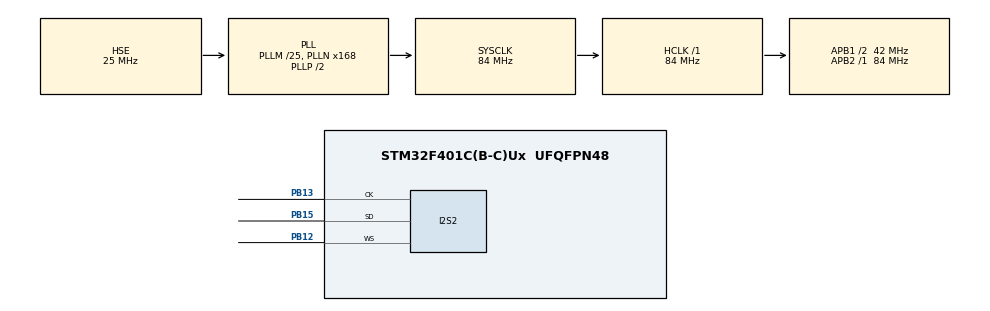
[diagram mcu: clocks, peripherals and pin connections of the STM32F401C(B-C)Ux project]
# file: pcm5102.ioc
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Dma.Request0=SPI2_TX
Dma.SPI2_TX.0.Direction=DMA_MEMORY_TO_PERIPH
Dma.SPI2_TX.0.FIFOMode=DMA_FIFOMODE_DISABLE
Dma.SPI2_TX.0.Instance=DMA1_Stream4
Dma.SPI2_TX.0.MemDataAlignment=DMA_MDATAALIGN_HALFWORD
Dma.SPI2_TX.0.MemInc=DMA_MINC_ENABLE
Dma.SPI2_TX.0.Mode=DMA_CIRCULAR
Dma.SPI2_TX.0.PeriphDataAlignment=DMA_PDATAALIGN_HALFWORD
Dma.SPI2_TX.0.PeriphInc=DMA_PINC_DISABLE
Dma.SPI2_TX.0.Priority=DMA_PRIORITY_LOW
I2S2.AudioFreq=I2S_AUDIOFREQ_48K
I2S2.ErrorAudioFreq=-0.79 %
I2S2.FullDuplexMode=I2S_FULLDUPLEXMODE_DISABLE
I2S2.Instance=SPI$Index
I2S2.RealAudioFreq=47.619 KHz
I2S2.Standard=I2S_STANDARD_PHILIPS
I2S2.VirtualMode=I2S_MODE_MASTER
Mcu.Family=STM32F4
Mcu.Name=STM32F401C(B-C)Ux
Mcu.Package=UFQFPN48
NVIC.DMA1_Stream4_IRQn=true\:0\:0\:false\:false\:true\:false\:true
NVIC.PriorityGroup=NVIC_PRIORITYGROUP_4
NVIC.TIM1_UP_TIM10_IRQn=true\:0\:0\:false\:false\:true\:true\:true
PA13.Mode=Serial_Wire
PA13.Signal=SYS_JTMS-SWDIO
PA14.Mode=Serial_Wire
PA14.Signal=SYS_JTCK-SWCLK
PB12.Mode=Half_Duplex_Master
PB12.Signal=I2S2_WS
PB13.Mode=Half_Duplex_Master
PB13.Signal=I2S2_CK
PB15.Mode=Half_Duplex_Master
PB15.Signal=I2S2_SD
PH0\ -\ OSC_IN.Mode=HSE-External-Oscillator
PH0\ -\ OSC_IN.Signal=RCC_OSC_IN
PH1\ -\ OSC_OUT.Mode=HSE-External-Oscillator
PH1\ -\ OSC_OUT.Signal=RCC_OSC_OUT
ProjectManager.HeapSize=0x200
ProjectManager.StackSize=0x400
ProjectManager.TargetToolchain=STM32CubeIDE
RCC.48MHZClocksFreq_Value=42000000
RCC.AHBFreq_Value=84000000
RCC.APB1CLKDivider=RCC_HCLK_DIV2
RCC.APB1Freq_Value=42000000
RCC.APB1TimFreq_Value=84000000
RCC.APB2Freq_Value=84000000
RCC.APB2TimFreq_Value=84000000
RCC.CortexFreq_Value=84000000
RCC.HCLKFreq_Value=84000000
RCC.HSE_VALUE=25000000
RCC.HSI_VALUE=16000000
RCC.LSE_VALUE=32768
RCC.PLLM=25
RCC.PLLN=168
RCC.PLLSourceVirtual=RCC_PLLSOURCE_HSE
RCC.SYSCLKFreq_VALUE=84000000
RCC.SYSCLKSource=RCC_SYSCLKSOURCE_PLLCLK
RCC.VCOOutputFreq_Value=168000000
TIM10.Period=8400-1
VP_TIM10_VS_ClockSourceINT.Mode=Enable_Timer
board=custom

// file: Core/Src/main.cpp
/* USER CODE BEGIN Header */
/**
  ******************************************************************************
  * @file           : main.c
  * @brief          : Main program body
  ******************************************************************************
  * @attention
  *
  * <h2><center>&copy; Copyright (c) 2021 STMicroelectronics.
  * All rights reserved.</center></h2>
  *
  * This software component is licensed by ST under BSD 3-Clause license,
  * the "License"; You may not use this file except in compliance with the
  * License. You may obtain a copy of the License at:
  *                        opensource.org/licenses/BSD-3-Clause
  *
  ******************************************************************************
  */
/* USER CODE END Header */
#include "main.h"
#include "i2s.h"
#include "gpio.h"
#include "dma.h"
#include "tim.h"

/* USER CODE BEGIN Includes */
//#include "lookuptable.h"
#include "wavetable.h"

#include "Karplus.h"
#include "Delay.h"

#include <cstdlib>
/* USER CODE END Includes */

/* USER CODE BEGIN PD */
#define BUFF_LEN_DIV2 512 // Audio buffer length
#define BUFF_LEN 1024     // Audio buffer length for both Left & Right Channels
/* USER CODE END PD */

void SystemClock_Config(void);

/* USER CODE BEGIN 0 */
Karplus karplus;
Delay delay;

uint16_t ms_cnt = 0;

uint16_t audiobuff[BUFF_LEN];

uint16_t once = 1;

void make_sound(uint16_t index) {
	uint16_t threshold = index + BUFF_LEN_DIV2;

	while(index <= threshold ) {
		karplus.get_karplus(0.5f);
		uint16_t val = (uint16_t)(karplus.out * 30000.0f);
		delay.process(val);
		audiobuff[index] = (uint16_t)(delay.out);
		audiobuff[index+1] = (uint16_t)(delay.out);
		index += 2;
	}
}
/* USER CODE END 0 */

int main(void)
{

  /* MCU Configuration--------------------------------------------------------*/

  /* Reset of all peripherals, Initializes the Flash interface and the Systick. */
  HAL_Init();

  /* Configure the system clock */
  SystemClock_Config();

  /* Initialize all configured peripherals */
  MX_GPIO_Init();
  MX_DMA_Init();
  MX_I2S2_Init();
  MX_TIM10_Init();
//  MX_TIM10_Init();
  /* USER CODE BEGIN 2 */
  HAL_TIM_Base_Start_IT(&htim10);
  HAL_I2S_Transmit_DMA(&hi2s2, (uint16_t *)audiobuff, BUFF_LEN);
  /* USER CODE END 2 */

  /* Infinite loop */
  /* USER CODE BEGIN WHILE */
  while (1)
  {
	  if(ms_cnt > 20000) {
		  ms_cnt = 0;
		  karplus.restore_freq((float)(rand() % 100 + 50));
	  }
//	  HAL_I2S_Transmit(&hi2s2, (uint16_t*)sine, 1024, HAL_MAX_DELAY);
    /* USER CODE END WHILE */

  }
}

void SystemClock_Config(void)
{
  RCC_OscInitTypeDef RCC_OscInitStruct = {0};
  RCC_ClkInitTypeDef RCC_ClkInitStruct = {0};
  RCC_PeriphCLKInitTypeDef PeriphClkInitStruct = {0};

  /** Configure the main internal regulator output voltage
  */
  __HAL_RCC_PWR_CLK_ENABLE();
  __HAL_PWR_VOLTAGESCALING_CONFIG(PWR_REGULATOR_VOLTAGE_SCALE2);
  /** Initializes the RCC Oscillators according to the specified parameters
  * in the RCC_OscInitTypeDef structure.
  */
  RCC_OscInitStruct.OscillatorType = RCC_OSCILLATORTYPE_HSE;
  RCC_OscInitStruct.HSEState = RCC_HSE_ON;
  RCC_OscInitStruct.PLL.PLLState = RCC_PLL_ON;
  RCC_OscInitStruct.PLL.PLLSource = RCC_PLLSOURCE_HSE;
  RCC_OscInitStruct.PLL.PLLM = 25;
  RCC_OscInitStruct.PLL.PLLN = 168;
  RCC_OscInitStruct.PLL.PLLP = RCC_PLLP_DIV2;
  RCC_OscInitStruct.PLL.PLLQ = 4;
  if (HAL_RCC_OscConfig(&RCC_OscInitStruct) != HAL_OK)
  {
    Error_Handler();
  }
  /** Initializes the CPU, AHB and APB buses clocks
  */
  RCC_ClkInitStruct.ClockType = RCC_CLOCKTYPE_HCLK|RCC_CLOCKTYPE_SYSCLK
                              |RCC_CLOCKTYPE_PCLK1|RCC_CLOCKTYPE_PCLK2;
  RCC_ClkInitStruct.SYSCLKSource = RCC_SYSCLKSOURCE_PLLCLK;
  RCC_ClkInitStruct.AHBCLKDivider = RCC_SYSCLK_DIV1;
  RCC_ClkInitStruct.APB1CLKDivider = RCC_HCLK_DIV2;
  RCC_ClkInitStruct.APB2CLKDivider = RCC_HCLK_DIV1;

  if (HAL_RCC_ClockConfig(&RCC_ClkInitStruct, FLASH_LATENCY_2) != HAL_OK)
  {
    Error_Handler();
  }
  PeriphClkInitStruct.PeriphClockSelection = RCC_PERIPHCLK_I2S;
  PeriphClkInitStruct.PLLI2S.PLLI2SN = 192;
  PeriphClkInitStruct.PLLI2S.PLLI2SR = 2;
  if (HAL_RCCEx_PeriphCLKConfig(&PeriphClkInitStruct) != HAL_OK)
  {
    Error_Handler();
  }
}

/* USER CODE BEGIN 4 */
void HAL_TIM_PeriodElapsedCallback(TIM_HandleTypeDef *htim){
	if(htim->Instance == TIM10){
		ms_cnt++;

	}
}

void HAL_I2S_TxHalfCpltCallback(I2S_HandleTypeDef *hi2s)
{
  make_sound(0);
}

void HAL_I2S_TxCpltCallback(I2S_HandleTypeDef *hi2s)
{
  make_sound(BUFF_LEN_DIV2);
}
/* USER CODE END 4 */

void Error_Handler(void)
{
}

/************************ (C) COPYRIGHT STMicroelectronics *****END OF FILE****/
